# PY32F040Exx register map
Vendor: Puya; Series: PY32F0; File version: 1.0.0
CPU: CM0+ r0p1, little endian, no MPU, no FPU, 4 interrupt priority bits
Registers are 32-bit, read-write, reset 0x0 unless marked. A register's access mark holds for its fields unless they carry their own. Offsets are from the block's base; [hi:lo] are bit positions; {n}, {i} and the like mark numbered series.

## EXTI — External interrupt/event controller
Base 0x40021800
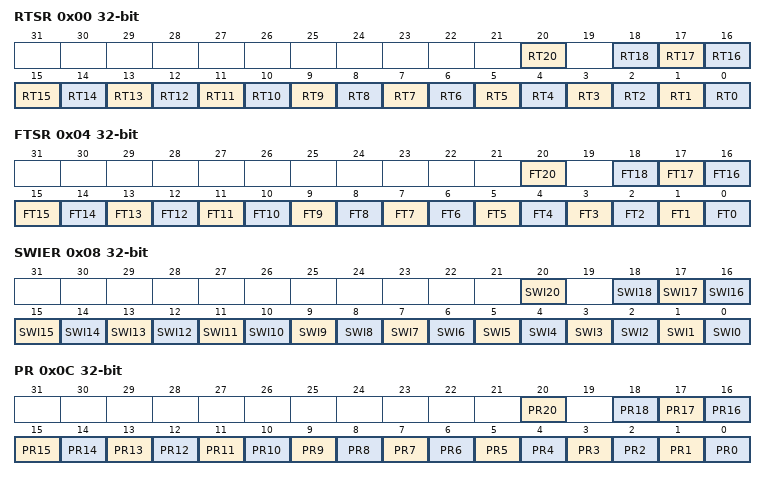
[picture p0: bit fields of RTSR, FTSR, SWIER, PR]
0x00 RTSR — EXTI rising trigger selection register
  [20] RT20 — Rising trigger event configuration bit of Configurable Event input
  [n] RT{n} (n=0..18) — Rising trigger event configuration bit of Configurable Event input
0x04 FTSR — EXTI falling trigger selection register
  [20] FT20 — Falling trigger event configuration bit of Configurable Event input
  [n] FT{n} (n=0..18) — Falling trigger event configuration bit of Configurable Event input
0x08 SWIER — EXTI software interrupt event register
  [20] SWI20 — Rising trigger event configuration bit of Configurable Event input
  [n] SWI{n} (n=0..18) — Rising trigger event configuration bit of Configurable Event input
0x0C PR — EXTI pending register
  [20] PR20 — configurable event inputs x rising edge Pending bit.
  [n] PR{n} (n=14..18) — configurable event inputs x rising edge Pending bit.
  [13] PR13 — configurable event inputs x rising edge Pending bit
  [n] PR{n} (n=0..12) — configurable event inputs x rising edge Pending bit.
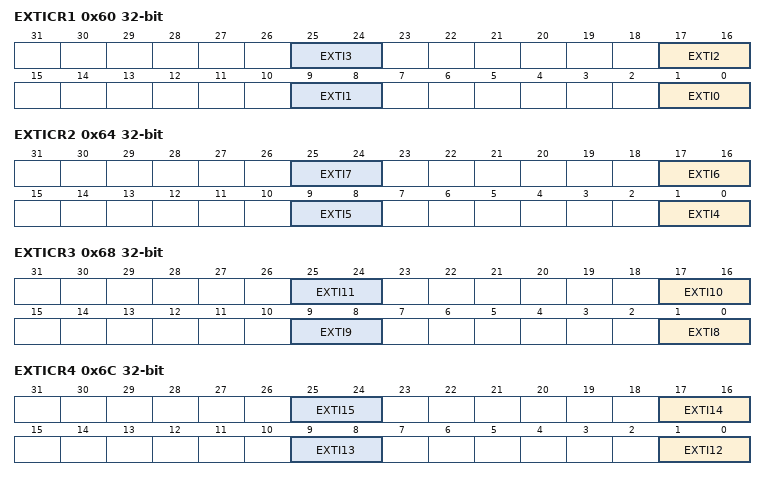
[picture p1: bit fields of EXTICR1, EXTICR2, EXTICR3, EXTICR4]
0x60 EXTICR1 — EXTI external interrupt selection register
  [8n+1:8n] EXTI{n} (n=0..3) — GPIO port selection
0x64 EXTICR2 — EXTI external interrupt selection register
  [8n-31:8n-32] EXTI{n} (n=4..7) — GPIO port selection
0x68 EXTICR3 — EXTI external interrupt selection register
  [8n-63:8n-64] EXTI{n} (n=8..11) — GPIO port selection
0x6C EXTICR4 — EXTI external interrupt selection register
  [8n-95:8n-96] EXTI{n} (n=12..15) — GPIO port selection
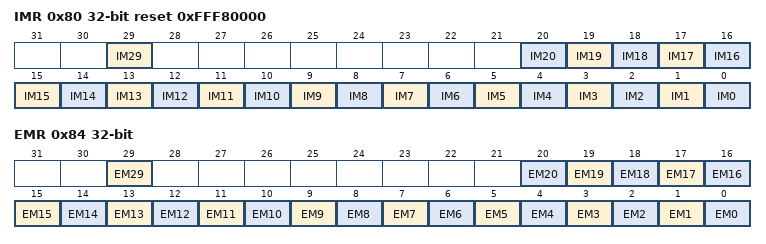
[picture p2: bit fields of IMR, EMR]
0x80 IMR reset 0xFFF80000 — EXTI CPU wakeup with interrupt mask register
  [29] IM29 — CPU wakeup with interrupt mask on event input
  [n] IM{n} (n=0..20) — CPU wakeup with interrupt mask on event input
0x84 EMR — EXTI CPU wakeup with event mask register
  [29] EM29 — CPU wakeup with event mask on event input
  [n] EM{n} (n=0..20) — CPU wakeup with event mask on event input

## FLASH
Base 0x40022000
0x00 ACR reset 0x500
  [1:0] LATENCY
0x08 KEYR wo
  [31:0] KEY
0x0C OPTKEYR wo
  [31:0] OPTKEY
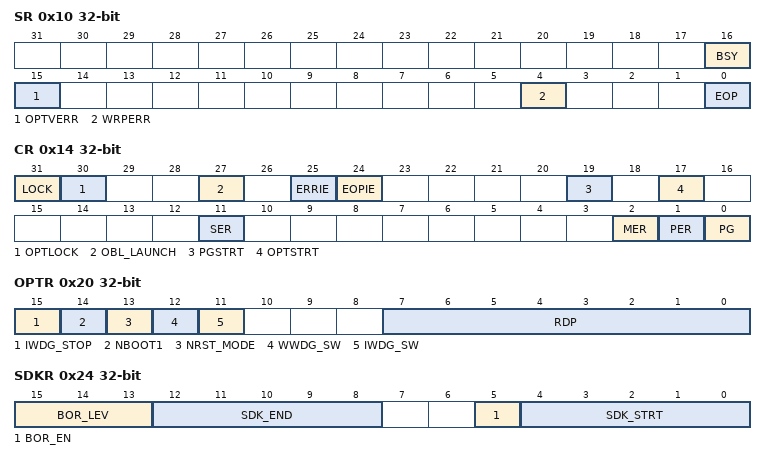
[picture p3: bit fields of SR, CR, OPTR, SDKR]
0x10 SR
  [16] BSY ro, [15] OPTVERR, [4] WRPERR, [0] EOP
0x14 CR
  [31] LOCK, [30] OPTLOCK, [27] OBL_LAUNCH, [25] ERRIE, [24] EOPIE, [19] PGSTRT, [17] OPTSTRT, [11] SER, [2] MER, [1] PER, [0] PG
0x20 OPTR ro
  [15] IWDG_STOP, [14] NBOOT1, [13] NRST_MODE, [12] WWDG_SW, [11] IWDG_SW, [7:0] RDP
0x24 SDKR ro
  [15:13] BOR_LEV, [12:8] SDK_END, [5] BOR_EN, [4:0] SDK_STRT
0x2C WRPR
  [15:0] WRP
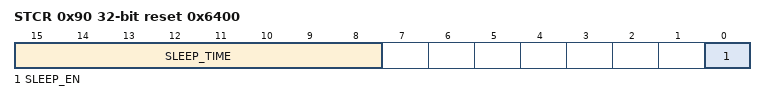
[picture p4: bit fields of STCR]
0x90 STCR reset 0x6400
  [15:8] SLEEP_TIME, [0] SLEEP_EN
0x100 TS0 reset 0xB4
  [7:0] TS0
0x104 TS1 reset 0x1B0
  [8:0] TS1
0x108 TS2P reset 0xB4
  [7:0] TS2P
0x10C TPS3 reset 0x6C0
  [10:0] TPS3
0x110 TS3 reset 0xB4
  [7:0] TS3
0x114 PERTPE reset 0xEA60
  [16:0] PERTPE
0x118 SMERTPE reset 0xFD20
  [16:0] SMERTPE
0x11C PRGTPE reset 0x8CA0
  [15:0] PRGTPE
0x120 PRETPE reset 0x12C0
  [13:0] PRETPE

## GPIOA — General-purpose I/Os
Base 0x50000000
Same registers: GPIOB 0x50000400, GPIOC 0x50000800, GPIOF 0x50001400
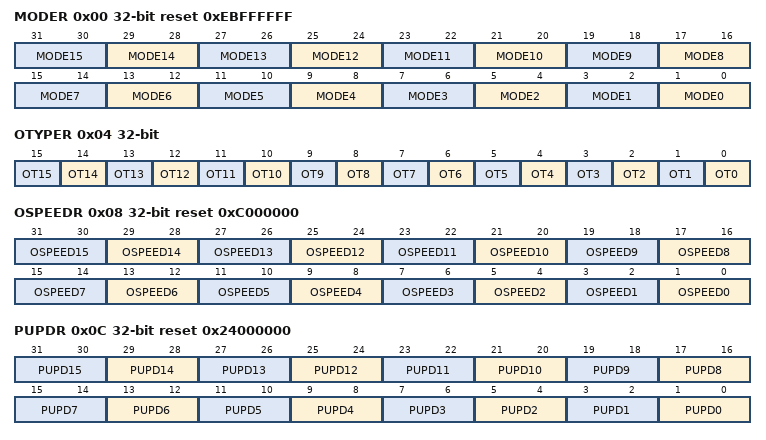
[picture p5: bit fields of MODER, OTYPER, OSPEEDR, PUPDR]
0x00 MODER reset 0xEBFFFFFF — GPIO port mode register
  [2n+1:2n] MODE{n} (n=0..15) — Port x configuration bits (y=0-15)
0x04 OTYPER — GPIO port output type register
  [n] OT{n} (n=0..15) — Port x configuration bits (y=0-15)
0x08 OSPEEDR reset 0xC000000 — GPIO port output speed register
  [2n+1:2n] OSPEED{n} (n=0..15) — Port x configuration bits (y=0-15)
0x0C PUPDR reset 0x24000000 — GPIO port pull-up/pull-down register
  [2n+1:2n] PUPD{n} (n=0..15) — Port x configuration bits (y=0-15)
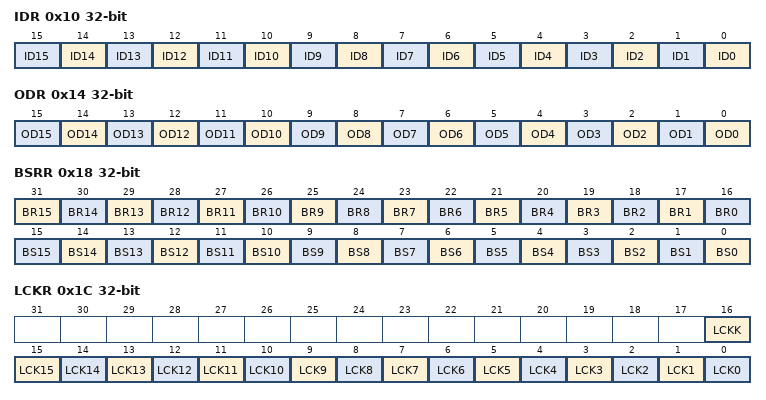
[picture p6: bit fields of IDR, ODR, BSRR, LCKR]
0x10 IDR ro — GPIO port input data register
  [n] ID{n} (n=0..15) — Port input data (y=0-15)
0x14 ODR — GPIO port output data register
  [n] OD{n} (n=0..15) — Port output data (y=0-15)
0x18 BSRR wo — GPIO port bit set/reset register
  [n+16] BR{n} (n=1..15) — Port x reset bit y (y=0-15)
  [16] BR0 — Port x set bit y (y=0-15)
  [n] BS{n} (n=0..15) — Port x set bit y (y=0-15)
0x1C LCKR — GPIO port configuration lock register
  [16] LCKK — Port x lock (LCKK)
  [n] LCK{n} (n=0..15) — Port x lock bit y (y=0-15)
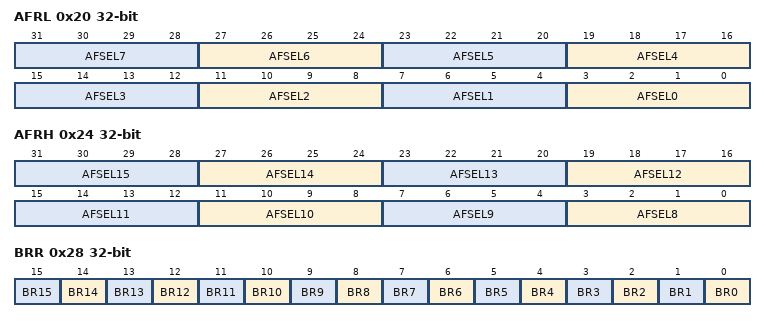
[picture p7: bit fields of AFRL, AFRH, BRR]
0x20 AFRL — GPIO alternate function low register
  [4n+3:4n] AFSEL{n} (n=0..7) — Alternate function selection for port x bit y (y=0-7)
0x24 AFRH — GPIO alternate function high register
  [4n-29:4n-32] AFSEL{n} (n=8..15) — Alternate function selection for port x bit y (y=8-15)
0x28 BRR wo — port bit reset register
  [n] BR{n} (n=0..15) — Port Reset bit
